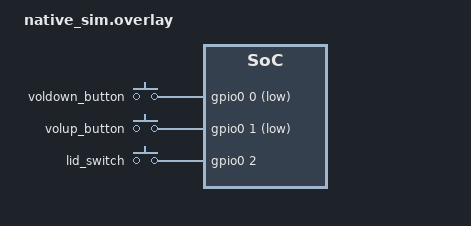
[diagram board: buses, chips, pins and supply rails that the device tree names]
/*
 * Copyright 2023 Google LLC
 *
 * SPDX-License-Identifier: Apache-2.0
 */

#include <zephyr/dt-bindings/input/input-event-codes.h>

&gpio0 {
	ngpios = <3>;
};

/ {
	buttons: gpio-keys0 {
		compatible = "gpio-keys";
		debounce-interval-ms = <30>;

		voldown_button: button_0 {
			gpios = <&gpio0 0 (GPIO_PULL_UP | GPIO_ACTIVE_LOW)>;
			zephyr,code = <10>;
		};

		volup_button: button_1 {
			gpios = <&gpio0 1 (GPIO_PULL_UP | GPIO_ACTIVE_LOW)>;
			zephyr,code = <11>;
		};

		lid_switch: switch_0 {
			gpios = <&gpio0 2 GPIO_ACTIVE_HIGH>;
			zephyr,code = <INPUT_SW_LID>;
			zephyr,input-type = <INPUT_EV_SW>;
		};
	};
};
